AUTOSAR XML (schema 4-0-3)
package /ComponentTypes
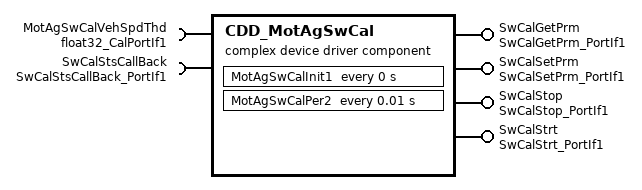
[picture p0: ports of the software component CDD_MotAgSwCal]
  complex device driver sw component type CDD_MotAgSwCal
    4 x provide port, all with server-com-spec{operation=Oper, queue-length=1}:
      SwCalGetPrm: provided-interface=SwCalGetPrm_PortIf1
      SwCalSetPrm: provided-interface=SwCalSetPrm_PortIf1
      SwCalStop: provided-interface=SwCalStop_PortIf1
      SwCalStrt: provided-interface=SwCalStrt_PortIf1
    require port MotAgSwCalVehSpdThd: parameter-require-com-spec{init-value=3, parameter=Val}, required-interface=float32_CalPortIf1
    require port SwCalStsCallBack: client-com-spec=Oper, required-interface=SwCalStsCallBack_PortIf1
    behavior CDD_MotAgSwCal_InternalBehavior
      ar-typed-per-instance-memorys:
        57 x data, all with sw-calibration-access=READ-ONLY:
          BoostModlnIdx: type=float32
          BoostSlew: type=float32
          BoostTi: type=uint8
          BoostTiOut: type=uint32
          CoolDwnModlnIdx: type=float32
          CoolDwnSlew: type=float32
          CoolDwnTi: type=uint16
          CoolDwnTiOut: type=uint32
          ElecRevCnt: type=uint8
          HldModlnIdx: type=float32
          HldSlew: type=float32
          HldTi: type=uint16
          HldTiOut: type=uint32
          MotAg2CosAdcFaildCntr: type=uint8
          MotAg2CosMeasAvrg: type=u3p13
          MotAg2CosMeasRaw: type=Ary1D_u3p13_50
          MotAg2CosMeasRawCumv: type=u3p13
          MotAg2CosMeasRawPrev: type=u3p13
          MotAg2SinAdcFaildCntr: type=uint8
          MotAg2SinMeasAvrg: type=u3p13
          MotAg2SinMeasRaw: type=Ary1D_u3p13_50
          MotAg2SinMeasRawCumv: type=u3p13
          MotAg2SinMeasRawPrev: type=u3p13
          MotAg5CosAdcFaildCntr: type=uint8
          MotAg5CosMeasAvrg: type=u3p13
          MotAg5CosMeasRaw: type=Ary1D_u3p13_50
          MotAg5CosMeasRawCumv: type=u3p13
          MotAg5CosMeasRawPrev: type=u3p13
          MotAg5SinAdcFaildCntr: type=uint8
          MotAg5SinMeasAvrg: type=u3p13
          MotAg5SinMeasRaw: type=Ary1D_u3p13_50
          MotAg5SinMeasRawCumv: type=u3p13
          MotAg5SinMeasRawPrev: type=u3p13
          MotAg6CosAdcFaildCntr: type=uint8
          MotAg6CosMeasAvrg: type=u3p13
          MotAg6CosMeasRaw: type=Ary1D_u3p13_50
          MotAg6CosMeasRawCumv: type=u3p13
          MotAg6CosMeasRawPrev: type=u3p13
          MotAg6SinAdcFaildCntr: type=uint8
          MotAg6SinMeasAvrg: type=u3p13
          MotAg6SinMeasRaw: type=Ary1D_u3p13_50
          MotAg6SinMeasRawCumv: type=u3p13
          MotAg6SinMeasRawPrev: type=u3p13
          PosnIdx: type=u16p16
          PosnStepSize: type=u0p16
          Ramp{1..3}Ti: type=uint8
          SampleIdx: type=uint8
          SamplePosnIdx: type=u16p16
          SampleRdyFlg: type=boolean
          SampleStopTi: type=uint32
          SampleStrtTi: type=uint32
          SwCalCycTi: type=uint32
          SwCalEna: type=boolean
          SwCalMotModlnIdx: type=float32
          SwCalStepDir: type=uint8
      timing event CDD_MotAgSwCal_InitEvent: start-on-event=MotAgSwCalInit1, period=0
      timing event TMT_MotAgSwCalPer2: start-on-event=MotAgSwCalPer2, period=0.01
      4 x operation invoked event:
        OIT_SwCalGetPrm_Oper_SwCalGetPrm_Oper: start-on-event=SwCalGetPrm_Oper, operation=SwCalGetPrm.Oper
        OIT_SwCalSetPrm_Oper_SwCalSetPrm_Oper: start-on-event=SwCalSetPrm_Oper, operation=SwCalSetPrm.Oper
        OIT_SwCalStop_Oper_SwCalStop_Oper: start-on-event=SwCalStop_Oper, operation=SwCalStop.Oper
        OIT_SwCalStrt_Oper_SwCalStrt_Oper: start-on-event=SwCalStrt_Oper, operation=SwCalStrt.Oper
      6 x runnable:
        MotAgSwCalInit1
        MotAgSwCalPer2
          sync call SC_SwCalStsCallBack_Oper: operation=SwCalStsCallBack.Oper, timeout=0
        SwCalGetPrm_Oper
        SwCalSetPrm_Oper
        SwCalStop_Oper
        SwCalStrt_Oper
  swc implementation CDD_MotAgSwCal_Implementation: behavior=CDD_MotAgSwCal_InternalBehavior
    code-descriptors:
      code Default: artifact-descriptors=autosar-engineering-object={short-label=Default, category=SWSRC}
